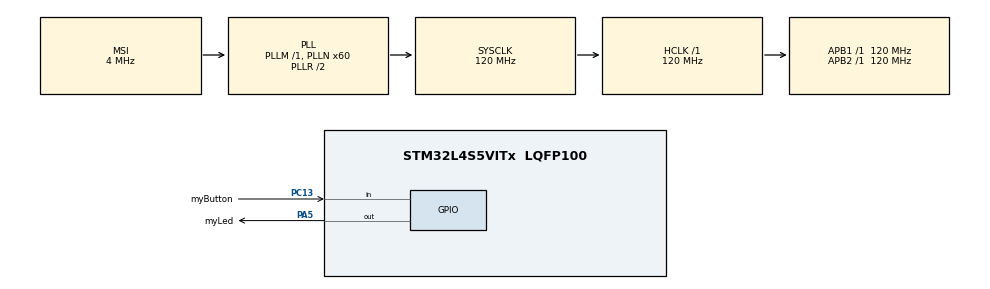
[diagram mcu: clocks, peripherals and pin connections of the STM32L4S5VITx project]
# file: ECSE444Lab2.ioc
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ADC1.Channel-0\#ChannelRegularConversion=ADC_CHANNEL_TEMPSENSOR
ADC1.NbrOfConversion=1
ADC1.NbrOfConversionFlag=1
ADC1.Resolution=ADC_RESOLUTION_12B
ADC1.SamplingTime-0\#ChannelRegularConversion=ADC_SAMPLETIME_47CYCLES_5
ADC1.master=1
Mcu.Family=STM32L4
Mcu.Name=STM32L4S5VITx
Mcu.Package=LQFP100
NVIC.PriorityGroup=NVIC_PRIORITYGROUP_4
PA5.GPIO_Label=myLed
PA5.Signal=GPIO_Output
PC13.GPIO_Label=myButton
PC13.Signal=GPIO_Input
ProjectManager.HeapSize=0x200
ProjectManager.StackSize=0x400
ProjectManager.TargetToolchain=STM32CubeIDE
RCC.ADCFreq_Value=48000000
RCC.AHBFreq_Value=120000000
RCC.APB1Freq_Value=120000000
RCC.APB1TimFreq_Value=120000000
RCC.APB2Freq_Value=120000000
RCC.APB2TimFreq_Value=120000000
RCC.CortexFreq_Value=120000000
RCC.HCLKFreq_Value=120000000
RCC.HSE_VALUE=8000000
RCC.HSI48_VALUE=48000000
RCC.HSI_VALUE=16000000
RCC.LSE_VALUE=32768
RCC.MSI_VALUE=4000000
RCC.PLLN=60
RCC.PLLSAI1N=24
RCC.SYSCLKFreq_VALUE=120000000
RCC.SYSCLKSource=RCC_SYSCLKSOURCE_PLLCLK
RCC.USBFreq_Value=48000000
RCC.VCOOutputFreq_Value=240000000
VP_ADC1_TempSens_Input.Mode=IN-TempSens
VP_ADC1_Vref_Input.Mode=IN-Vrefint
board=B-L4S5I-IOT01A

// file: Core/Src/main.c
/* USER CODE BEGIN Header */
/**
  ******************************************************************************
  * @file           : main.c
  * @brief          : Main program body
  ******************************************************************************
  * @attention
  *
  * Copyright (c) 2023 STMicroelectronics.
  * All rights reserved.
  *
  * This software is licensed under terms that can be found in the LICENSE file
  * in the root directory of this software component.
  * If no LICENSE file comes with this software, it is provided AS-IS.
  *
  ******************************************************************************
  */
/* USER CODE END Header */
#include "main.h"

#define VREFINT *(uint16_t*)(uint32_t)0x1FFF75AA
#define TS_CAL1 *(uint16_t*)(uint32_t)0x1FFF75A8
#define TS_CAL2 *(uint16_t*)(uint32_t)0x1FFF75CA
#define TS_CAL2_TEMP 130
#define TS_CAL1_TEMP 30

ADC_HandleTypeDef hadc1;

void SystemClock_Config(void);
static void MX_GPIO_Init(void);
static void MX_ADC1_Init(void);
static void toggleTemperature(int);

int main(void)
{

  /* MCU Configuration--------------------------------------------------------*/

  /* Reset of all peripherals, Initializes the Flash interface and the Systick. */
  HAL_Init();

  /* Configure the system clock */
  SystemClock_Config();

  /* Initialize all configured peripherals */
  MX_GPIO_Init();
  MX_ADC1_Init();

  /* Infinite loop */
  /* USER CODE BEGIN WHILE */
  float CALIBRATION_CONSTANT = (float)(TS_CAL2_TEMP - TS_CAL1_TEMP) / (float)(TS_CAL2 - TS_CAL1);
  while (1)
  {
    /* USER CODE END WHILE */
  uint8_t status = 0;
  float vref_ratio=1, vref, temperature=0;
  uint16_t adc_value;

  while (1)
  {

	status = HAL_GPIO_ReadPin(myButton_GPIO_Port, myButton_Pin);
	if(status == 0)
	{
		HAL_GPIO_WritePin(myLed_GPIO_Port, myLed_Pin, GPIO_PIN_SET);
		toggleTemperature(1);
		HAL_ADC_Start(&hadc1);
		HAL_ADC_PollForConversion(&hadc1, HAL_MAX_DELAY);
	 	adc_value = HAL_ADC_GetValue(&hadc1);
		temperature = CALIBRATION_CONSTANT * (float)(adc_value * vref_ratio - TS_CAL1) + 30;

	}else{
		HAL_GPIO_WritePin(myLed_GPIO_Port, myLed_Pin, GPIO_PIN_RESET);
		toggleTemperature(0);
		HAL_ADC_Start(&hadc1);
		HAL_ADC_PollForConversion(&hadc1, HAL_MAX_DELAY);
	 	adc_value = HAL_ADC_GetValue(&hadc1);
		vref_ratio = (float)VREFINT / (float)HAL_ADC_GetValue(&hadc1);
		vref = vref_ratio * 3;
	}

  }
  }
}

void SystemClock_Config(void)
{
  RCC_OscInitTypeDef RCC_OscInitStruct = {0};
  RCC_ClkInitTypeDef RCC_ClkInitStruct = {0};

  /** Configure the main internal regulator output voltage
  */
  if (HAL_PWREx_ControlVoltageScaling(PWR_REGULATOR_VOLTAGE_SCALE1_BOOST) != HAL_OK)
  {
    Error_Handler();
  }

  /** Initializes the RCC Oscillators according to the specified parameters
  * in the RCC_OscInitTypeDef structure.
  */
  RCC_OscInitStruct.OscillatorType = RCC_OSCILLATORTYPE_MSI;
  RCC_OscInitStruct.MSIState = RCC_MSI_ON;
  RCC_OscInitStruct.MSICalibrationValue = 0;
  RCC_OscInitStruct.MSIClockRange = RCC_MSIRANGE_6;
  RCC_OscInitStruct.PLL.PLLState = RCC_PLL_ON;
  RCC_OscInitStruct.PLL.PLLSource = RCC_PLLSOURCE_MSI;
  RCC_OscInitStruct.PLL.PLLM = 1;
  RCC_OscInitStruct.PLL.PLLN = 60;
  RCC_OscInitStruct.PLL.PLLP = RCC_PLLP_DIV2;
  RCC_OscInitStruct.PLL.PLLQ = RCC_PLLQ_DIV2;
  RCC_OscInitStruct.PLL.PLLR = RCC_PLLR_DIV2;
  if (HAL_RCC_OscConfig(&RCC_OscInitStruct) != HAL_OK)
  {
    Error_Handler();
  }

  /** Initializes the CPU, AHB and APB buses clocks
  */
  RCC_ClkInitStruct.ClockType = RCC_CLOCKTYPE_HCLK|RCC_CLOCKTYPE_SYSCLK
                              |RCC_CLOCKTYPE_PCLK1|RCC_CLOCKTYPE_PCLK2;
  RCC_ClkInitStruct.SYSCLKSource = RCC_SYSCLKSOURCE_PLLCLK;
  RCC_ClkInitStruct.AHBCLKDivider = RCC_SYSCLK_DIV1;
  RCC_ClkInitStruct.APB1CLKDivider = RCC_HCLK_DIV1;
  RCC_ClkInitStruct.APB2CLKDivider = RCC_HCLK_DIV1;

  if (HAL_RCC_ClockConfig(&RCC_ClkInitStruct, FLASH_LATENCY_5) != HAL_OK)
  {
    Error_Handler();
  }
}

static void MX_ADC1_Init(void)
{

  ADC_ChannelConfTypeDef sConfig = {0};

  /** Common config
  */
  hadc1.Instance = ADC1;
  hadc1.Init.ClockPrescaler = ADC_CLOCK_ASYNC_DIV1;
  hadc1.Init.Resolution = ADC_RESOLUTION_12B;
  hadc1.Init.DataAlign = ADC_DATAALIGN_RIGHT;
  hadc1.Init.ScanConvMode = ADC_SCAN_DISABLE;
  hadc1.Init.EOCSelection = ADC_EOC_SINGLE_CONV;
  hadc1.Init.LowPowerAutoWait = DISABLE;
  hadc1.Init.ContinuousConvMode = DISABLE;
  hadc1.Init.NbrOfConversion = 1;
  hadc1.Init.DiscontinuousConvMode = DISABLE;
  hadc1.Init.ExternalTrigConv = ADC_SOFTWARE_START;
  hadc1.Init.ExternalTrigConvEdge = ADC_EXTERNALTRIGCONVEDGE_NONE;
  hadc1.Init.DMAContinuousRequests = DISABLE;
  hadc1.Init.Overrun = ADC_OVR_DATA_PRESERVED;
  hadc1.Init.OversamplingMode = DISABLE;
  if (HAL_ADC_Init(&hadc1) != HAL_OK)
  {
    Error_Handler();
  }

  /** Configure Regular Channel
  */
  sConfig.Channel = ADC_CHANNEL_VREFINT;
  sConfig.Rank = ADC_REGULAR_RANK_1;
  sConfig.SamplingTime = ADC_SAMPLETIME_12CYCLES_5;
  sConfig.SingleDiff = ADC_SINGLE_ENDED;
  sConfig.OffsetNumber = ADC_OFFSET_NONE;
  sConfig.Offset = 0;
  if (HAL_ADC_ConfigChannel(&hadc1, &sConfig) != HAL_OK)
  {
    Error_Handler();
  }

}

static void toggleTemperature(int temperature)
{
	ADC_ChannelConfTypeDef sConfig = {0};
	if(temperature)
	{
		sConfig.Channel = ADC_CHANNEL_TEMPSENSOR;
	}else{
		sConfig.Channel = ADC_CHANNEL_VREFINT;
	}

	sConfig.Rank = ADC_REGULAR_RANK_1;
	sConfig.SamplingTime = ADC_SAMPLETIME_12CYCLES_5;
	sConfig.SingleDiff = ADC_SINGLE_ENDED;
	sConfig.OffsetNumber = ADC_OFFSET_NONE;
	sConfig.Offset = 0;
	if (HAL_ADC_ConfigChannel(&hadc1, &sConfig) != HAL_OK)
	{
		Error_Handler();
	}
}

static void MX_GPIO_Init(void)
{
  GPIO_InitTypeDef GPIO_InitStruct = {0};

  /* GPIO Ports Clock Enable */
  __HAL_RCC_GPIOC_CLK_ENABLE();
  __HAL_RCC_GPIOA_CLK_ENABLE();

  /*Configure GPIO pin Output Level */
  HAL_GPIO_WritePin(myLed_GPIO_Port, myLed_Pin, GPIO_PIN_RESET);

  /*Configure GPIO pin : myButton_Pin */
  GPIO_InitStruct.Pin = myButton_Pin;
  GPIO_InitStruct.Mode = GPIO_MODE_INPUT;
  GPIO_InitStruct.Pull = GPIO_NOPULL;
  HAL_GPIO_Init(myButton_GPIO_Port, &GPIO_InitStruct);

  /*Configure GPIO pin : myLed_Pin */
  GPIO_InitStruct.Pin = myLed_Pin;
  GPIO_InitStruct.Mode = GPIO_MODE_OUTPUT_PP;
  GPIO_InitStruct.Pull = GPIO_NOPULL;
  GPIO_InitStruct.Speed = GPIO_SPEED_FREQ_LOW;
  HAL_GPIO_Init(myLed_GPIO_Port, &GPIO_InitStruct);

}

void Error_Handler(void)
{
  __disable_irq();
  while (1)
  {
  }
}
